# ATmega32 device description
Architecture: AVR8; Family: megaAVR
Registers are 8-bit, access not given, no defined reset value unless marked. A register's access mark holds for its fields unless they carry their own. Offsets are from the block's base; [hi:lo] are bit positions.

## TC1 (TC16 module) — Timer/Counter, 16-bit
Instances: TC1 0x00
0x46 ICR1 16-bit — Timer/Counter1 Input Capture Register Bytes
0x48 OCR1B 16-bit — Timer/Counter1 Output Compare Register Bytes
0x4A OCR1A 16-bit — Timer/Counter1 Output Compare Register Bytes
0x4C TCNT1 16-bit — Timer/Counter1 Bytes
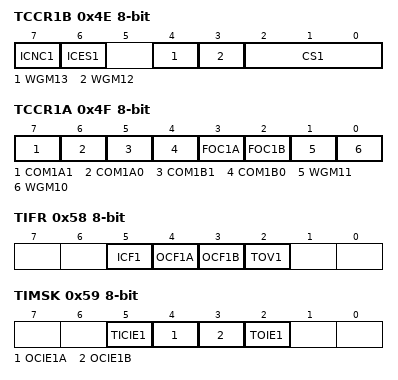
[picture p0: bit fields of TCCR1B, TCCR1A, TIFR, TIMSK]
0x4E TCCR1B — Timer/Counter1 Control Register B
  [7] ICNC1 — Input Capture 1 Noise Canceler
  [6] ICES1 — Input Capture 1 Edge Select
  [4] WGM13 (bit 2 of the value upward) — Waveform Generation Mode
  [3] WGM12 (bit 2 of the value upward) — Waveform Generation Mode
  [2:0] CS1 — Prescaler source of Timer/Counter 1
    0=No Clock Source (Stopped); 1=Running, No Prescaling; 2=Running, CLK/8; 3=Running, CLK/64; 4=Running, CLK/256; 5=Running, CLK/1024; 6=Running, ExtClk Tx Falling Edge; 7=Running, ExtClk Tx Rising Edge
0x4F TCCR1A — Timer/Counter1 Control Register A
  [7] COM1A1 — Compare Output Mode 1A, bits
  [6] COM1A0 — Compare Output Mode 1A, bits
  [5] COM1B1 — Compare Output Mode 1B, bits
  [4] COM1B0 — Compare Output Mode 1B, bits
  [3] FOC1A — Force Output Compare 1A
  [2] FOC1B — Force Output Compare 1B
  [1] WGM11 — Waveform Generation Mode
  [0] WGM10 — Waveform Generation Mode
0x58 TIFR — Timer/Counter Interrupt Flag register
  [5] ICF1 — Input Capture Flag 1
  [4] OCF1A — Output Compare Flag 1A
  [3] OCF1B — Output Compare Flag 1B
  [2] TOV1 — Timer/Counter1 Overflow Flag
0x59 TIMSK — Timer/Counter Interrupt Mask Register
  [5] TICIE1 — Timer/Counter1 Input Capture Interrupt Enable
  [4] OCIE1A — Timer/Counter1 Output CompareA Match Interrupt Enable
  [3] OCIE1B — Timer/Counter1 Output CompareB Match Interrupt Enable
  [2] TOIE1 — Timer/Counter1 Overflow Interrupt Enable

## SPI — Serial Peripheral Interface
Instances: SPI 0x00
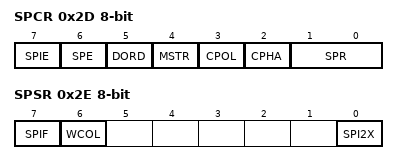
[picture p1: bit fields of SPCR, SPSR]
0x2D SPCR — SPI Control Register
  [7] SPIE — SPI Interrupt Enable
  [6] SPE — SPI Enable
  [5] DORD — Data Order
  [4] MSTR — Master/Slave Select
  [3] CPOL — Clock polarity
  [2] CPHA — Clock Phase
  [1:0] SPR — SPI Clock Rate Selects
    0=fosc/4; 1=fosc/16; 2=fosc/64; 3=fosc/128; 4=fosc/2; 5=fosc/8; 6=fosc/32; 7=fosc/64
0x2E SPSR — SPI Status Register
  [7] SPIF — SPI Interrupt Flag
  [6] WCOL — Write Collision Flag
  [0] SPI2X — Double SPI Speed Bit
0x2F SPDR — SPI Data Register

## USART
Instances: USART 0x00
0x29 UBRRL — USART Baud Rate Register Low Byte
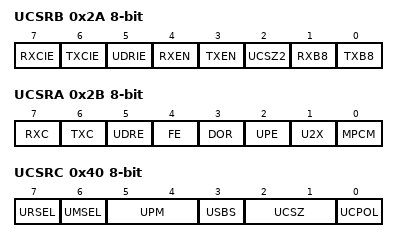
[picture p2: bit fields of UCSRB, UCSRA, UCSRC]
0x2A UCSRB — USART Control and Status Register B
  [7] RXCIE — RX Complete Interrupt Enable
  [6] TXCIE — TX Complete Interrupt Enable
  [5] UDRIE — USART Data register Empty Interrupt Enable
  [4] RXEN — Receiver Enable
  [3] TXEN — Transmitter Enable
  [2] UCSZ2 — Character Size
  [1] RXB8 — Receive Data Bit 8
  [0] TXB8 — Transmit Data Bit 8
0x2B UCSRA — USART Control and Status Register A
  [7] RXC — USART Receive Complete
  [6] TXC — USART Transmitt Complete
  [5] UDRE — USART Data Register Empty
  [4] FE — Framing Error
  [3] DOR — Data overRun
  [2] UPE — Parity Error
  [1] U2X — Double the USART transmission speed
  [0] MPCM — Multi-processor Communication Mode
0x2C UDR — USART I/O Data Register
0x40 UCSRC — USART Control and Status Register C
  [7] URSEL — Register Select
  [6] UMSEL — USART Mode Select
    0=Asynchronous Operation; 1=Synchronous Operation
  [5:4] UPM — Parity Mode Bits
    0=Disabled; 2=Enabled, Even Parity; 3=Enabled, Odd Parity
  [3] USBS — Stop Bit Select
    0=1-bit; 1=2-bit
  [2:1] UCSZ — Character Size
  [0] UCPOL — Clock Polarity
0x40 UBRRH bits used 3:0 — USART Baud Rate Register Hight Byte

## AC — Analog Comparator
Instances: AC 0x00
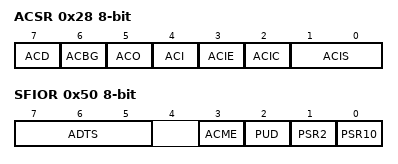
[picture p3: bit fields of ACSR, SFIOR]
0x28 ACSR — Analog Comparator Control And Status Register
  [7] ACD — Analog Comparator Disable
  [6] ACBG — Analog Comparator Bandgap Select
  [5] ACO — Analog Compare Output
  [4] ACI — Analog Comparator Interrupt Flag
  [3] ACIE — Analog Comparator Interrupt Enable
  [2] ACIC — Analog Comparator Input Capture Enable
  [1:0] ACIS — Analog Comparator Interrupt Mode Select bits
    0=Interrupt on Toggle; 2=Interrupt on Falling Edge; 3=Interrupt on Rising Edge
0x50 SFIOR — Special Function IO Register
  [7:5] ADTS — ADC Auto Trigger Source
  [3] ACME — Analog Comparator Multiplexer Enable
  [2] PUD — Pull-up disable
  [1] PSR2 — Prescaler Reset Timer/Counter2
  [0] PSR10 — Prescaler Reset Timer/Counter1 and Timer/Counter0
